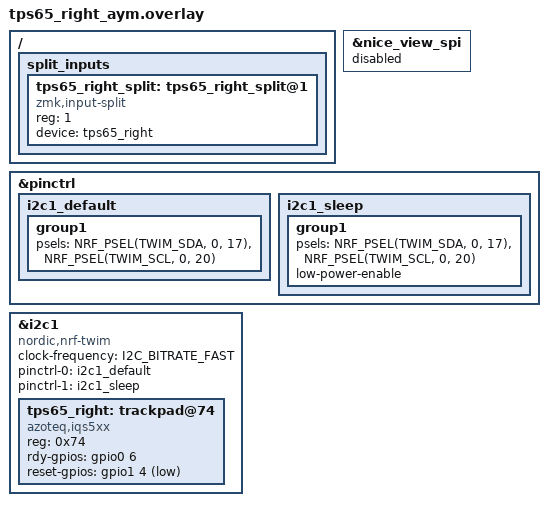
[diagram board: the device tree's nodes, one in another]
/*
 * Test (task 04c step 10e E5): Azoteq TPS65 (IQS550, I2C 0x74) on the right half
 * with the AYM1607 driver (compatible "azoteq,iqs5xx").
 * Same pins as tps65_right:
 *   SDA = P0.17 (P1), SCL = P0.20 (P4), RDY = P0.06 (P3), RST = P1.04 (header 1.04).
 * Version D has no display, so spi0 (nice!view) is off and its pins go to i2c1.
 */

#include <zephyr/dt-bindings/gpio/gpio.h>

&nice_view_spi {
    status = "disabled";
};

&pinctrl {
    i2c1_default: i2c1_default {
        group1 {
            psels = <NRF_PSEL(TWIM_SDA, 0, 17)>,
                    <NRF_PSEL(TWIM_SCL, 0, 20)>;
        };
    };

    i2c1_sleep: i2c1_sleep {
        group1 {
            psels = <NRF_PSEL(TWIM_SDA, 0, 17)>,
                    <NRF_PSEL(TWIM_SCL, 0, 20)>;
            low-power-enable;
        };
    };
};

&i2c1 {
    status = "okay";
    compatible = "nordic,nrf-twim";
    clock-frequency = <I2C_BITRATE_FAST>;
    pinctrl-0 = <&i2c1_default>;
    pinctrl-1 = <&i2c1_sleep>;
    pinctrl-names = "default", "sleep";

    tps65_right: trackpad@74 {
        compatible = "azoteq,iqs5xx";
        reg = <0x74>;
        status = "okay";

        rdy-gpios = <&gpio0 6 GPIO_ACTIVE_HIGH>;
        /* RST is active low; this driver uses the active-low flag (see its README). */
        reset-gpios = <&gpio1 4 GPIO_ACTIVE_LOW>;

        /* No gestures: no taps, press-and-hold or scroll. The pad only reports X/Y. */
    };
};

/ {
    split_inputs {
        #address-cells = <1>;
        #size-cells = <0>;

        tps65_right_split: tps65_right_split@1 {
            compatible = "zmk,input-split";
            reg = <1>;
            device = <&tps65_right>;
        };
    };
};
